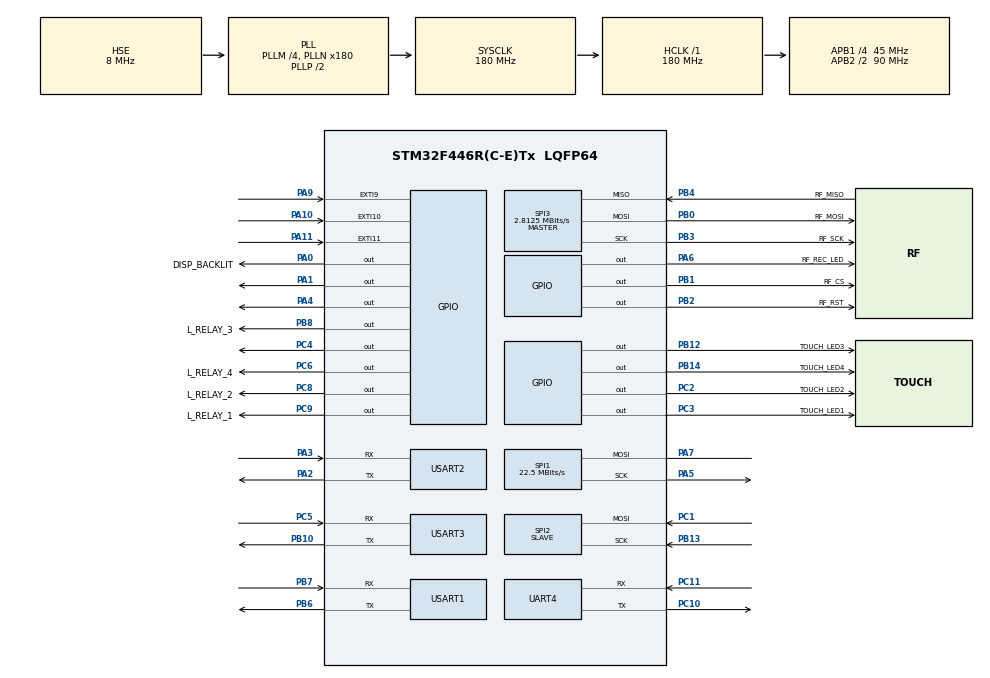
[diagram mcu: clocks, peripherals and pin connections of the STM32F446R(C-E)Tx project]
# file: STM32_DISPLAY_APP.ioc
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FATFS._USE_LABEL=1
IWDG.Prescaler=IWDG_PRESCALER_64
IWDG.Reload=1500
Mcu.Family=STM32F4
Mcu.Name=STM32F446R(C-E)Tx
Mcu.Package=LQFP64
NVIC.EXTI15_10_IRQn=true\:0\:0\:false\:false\:true\:true\:true\:true
NVIC.EXTI9_5_IRQn=true\:0\:0\:false\:false\:true\:true\:true\:true
NVIC.PriorityGroup=NVIC_PRIORITYGROUP_4
NVIC.RTC_Alarm_IRQn=true\:7\:0\:true\:false\:true\:true\:true\:true
NVIC.SPI2_IRQn=true\:5\:0\:true\:false\:true\:true\:true\:true
NVIC.TIM1_UP_TIM10_IRQn=true\:15\:0\:false\:false\:true\:false\:true\:true
NVIC.TimeBase=TIM1_UP_TIM10_IRQn
NVIC.TimeBaseIP=TIM1
NVIC.UART4_IRQn=true\:0\:0\:false\:false\:true\:true\:true\:true
NVIC.USART3_IRQn=true\:6\:0\:true\:false\:true\:true\:true\:true
PA0-WKUP.GPIO_Label=DISP_BACKLIT
PA0-WKUP.Signal=GPIO_Output
PA1.Signal=GPIO_Output
PA10.GPIO_ModeDefaultEXTI=GPIO_MODE_IT_FALLING
PA10.GPIO_PuPd=GPIO_PULLDOWN
PA10.Signal=GPXTI10
PA11.GPIO_ModeDefaultEXTI=GPIO_MODE_IT_FALLING
PA11.GPIO_PuPd=GPIO_PULLDOWN
PA11.Signal=GPXTI11
PA2.Mode=Asynchronous
PA2.Signal=USART2_TX
PA3.Mode=Asynchronous
PA3.Signal=USART2_RX
PA4.Signal=GPIO_Output
PA5.Mode=Simplex_Bidirectional_Master
PA5.Signal=SPI1_SCK
PA6.GPIO_Label=RF_REC_LED
PA6.Signal=GPIO_Output
PA7.Mode=Simplex_Bidirectional_Master
PA7.Signal=SPI1_MOSI
PA9.GPIO_ModeDefaultEXTI=GPIO_MODE_IT_FALLING
PA9.GPIO_PuPd=GPIO_PULLDOWN
PA9.Signal=GPXTI9
PB0.GPIO_Label=RF_MOSI
PB0.Mode=Full_Duplex_Master
PB0.Signal=SPI3_MOSI
PB1.GPIO_Label=RF_CS
PB1.Signal=GPIO_Output
PB10.Mode=Asynchronous
PB10.Signal=USART3_TX
PB12.GPIO_Label=TOUCH_LED3
PB12.Signal=GPIO_Output
PB13.Mode=RX_Only_Simplex_Unidirect_Slave
PB13.Signal=SPI2_SCK
PB14.GPIO_Label=TOUCH_LED4
PB14.Signal=GPIO_Output
PB2.GPIO_Label=RF_RST
PB2.Signal=GPIO_Output
PB3.GPIO_Label=RF_SCK
PB3.Mode=Full_Duplex_Master
PB3.Signal=SPI3_SCK
PB4.GPIO_Label=RF_MISO
PB4.Mode=Full_Duplex_Master
PB4.Signal=SPI3_MISO
PB6.Mode=Asynchronous
PB6.Signal=USART1_TX
PB7.Mode=Asynchronous
PB7.Signal=USART1_RX
PB8.GPIO_Label=L_RELAY_3
PB8.PinState=GPIO_PIN_SET
PB8.Signal=GPIO_Output
PC1.Mode=RX_Only_Simplex_Unidirect_Slave
PC1.Signal=SPI2_MOSI
PC10.Mode=Asynchronous
PC10.Signal=UART4_TX
PC11.Mode=Asynchronous
PC11.Signal=UART4_RX
PC14-OSC32_IN.Mode=LSE-External-Oscillator
PC14-OSC32_IN.Signal=RCC_OSC32_IN
PC15-OSC32_OUT.Mode=LSE-External-Oscillator
PC15-OSC32_OUT.Signal=RCC_OSC32_OUT
PC2.GPIO_Label=TOUCH_LED2
PC2.Signal=GPIO_Output
PC3.GPIO_Label=TOUCH_LED1
PC3.Signal=GPIO_Output
PC4.Signal=GPIO_Output
PC5.Mode=Asynchronous
PC5.Signal=USART3_RX
PC6.GPIO_Label=L_RELAY_4
PC6.GPIO_PuPd=GPIO_PULLDOWN
PC6.PinState=GPIO_PIN_RESET
PC6.Signal=GPIO_Output
PC8.GPIO_Label=L_RELAY_2
PC8.PinState=GPIO_PIN_SET
PC8.Signal=GPIO_Output
PC9.GPIO_Label=L_RELAY_1
PC9.PinState=GPIO_PIN_SET
PC9.Signal=GPIO_Output
PH0-OSC_IN.Mode=HSE-External-Oscillator
PH0-OSC_IN.Signal=RCC_OSC_IN
PH1-OSC_OUT.Mode=HSE-External-Oscillator
PH1-OSC_OUT.Signal=RCC_OSC_OUT
ProjectManager.HeapSize=0x200
ProjectManager.StackSize=0x400
ProjectManager.TargetToolchain=STM32CubeIDE
RCC.AHBFreq_Value=180000000
RCC.APB1CLKDivider=RCC_HCLK_DIV4
RCC.APB1Freq_Value=45000000
RCC.APB1TimFreq_Value=90000000
RCC.APB2CLKDivider=RCC_HCLK_DIV2
RCC.APB2Freq_Value=90000000
RCC.APB2TimFreq_Value=180000000
RCC.CortexFreq_Value=180000000
RCC.HCLKFreq_Value=180000000
RCC.HSE_VALUE=8000000
RCC.PLLM=4
RCC.PLLN=180
RCC.PLLSourceVirtual=RCC_PLLSOURCE_HSE
RCC.RCC_RTC_Clock_SourceVirtual=RCC_RTCCLKSOURCE_LSE
RCC.SYSCLKFreq_VALUE=180000000
RCC.SYSCLKSource=RCC_SYSCLKSOURCE_PLLCLK
RCC.USBFreq_Value=180000000
RCC.VCOOutputFreq_Value=360000000
RTC.Alarm=RTC_ALARM_A
RTC.Alarm_B=RTC_ALARM_B
RTC.HourFormat=RTC_HOURFORMAT_24
SPI1.BaudRatePrescaler=SPI_BAUDRATEPRESCALER_4
SPI1.CalculateBaudRate=22.5 MBits/s
SPI1.Direction=SPI_DIRECTION_1LINE
SPI1.Mode=SPI_MODE_MASTER
SPI1.VirtualType=VM_MASTER
SPI2.Direction=SPI_DIRECTION_2LINES_RXONLY
SPI2.Mode=SPI_MODE_SLAVE
SPI2.VirtualType=VM_SLAVE
SPI3.BaudRatePrescaler=SPI_BAUDRATEPRESCALER_16
SPI3.CalculateBaudRate=2.8125 MBits/s
SPI3.Direction=SPI_DIRECTION_2LINES
SPI3.Mode=SPI_MODE_MASTER
SPI3.VirtualType=VM_MASTER
UART4.VirtualMode=Asynchronous
USART1.VirtualMode=VM_ASYNC
USART2.VirtualMode=VM_ASYNC
USART3.VirtualMode=VM_ASYNC
VP_FATFS_VS_Generic.Mode=User_defined
VP_IWDG_VS_IWDG.Mode=IWDG_Activate
VP_RTC_VS_RTC_Activate.Mode=RTC_Enabled
VP_RTC_VS_RTC_Alarm_A_Intern.Mode=Alarm A
VP_RTC_VS_RTC_Alarm_B_Intern.Mode=Alarm B
VP_RTC_VS_RTC_Calendar.Mode=RTC_Calendar
VP_SYS_VS_tim1.Mode=TIM1
board=custom

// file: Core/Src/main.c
/* USER CODE BEGIN Header */
/**
  ******************************************************************************
  * @file           : main.c
  * @brief          : Main program body
  ******************************************************************************
  * @attention
  *
  * Copyright (c) 2025 STMicroelectronics.
  * All rights reserved.
  *
  * This software is licensed under terms that can be found in the LICENSE file
  * in the root directory of this software component.
  * If no LICENSE file comes with this software, it is provided AS-IS.
  *
  ******************************************************************************
  */
/* USER CODE END Header */
#include "main.h"
#include "fatfs.h"

/* USER CODE BEGIN Includes */
#include "user_app.h"
/* USER CODE END Includes */

IWDG_HandleTypeDef hiwdg;

RTC_HandleTypeDef hrtc;

SPI_HandleTypeDef hspi1;
SPI_HandleTypeDef hspi2;
SPI_HandleTypeDef hspi3;

UART_HandleTypeDef huart4;
UART_HandleTypeDef huart1;
UART_HandleTypeDef huart2;
UART_HandleTypeDef huart3;

void SystemClock_Config(void);
static void MX_GPIO_Init(void);
static void MX_SPI1_Init(void);
static void MX_SPI2_Init(void);
static void MX_USART2_UART_Init(void);
static void MX_USART3_UART_Init(void);
static void MX_SPI3_Init(void);
static void MX_UART4_Init(void);
static void MX_USART1_UART_Init(void);
static void MX_RTC_Init(void);
void MX_IWDG_Init(void);

/* USER CODE BEGIN 0 */
#ifdef __GNUC__
#define UART_printf   int __io_putchar(int ch)
UART_printf
{
	HAL_UART_Transmit(&huart2, (uint8_t*)&ch, 1, HAL_MAX_DELAY);
	return ch;
}
#endif
/* USER CODE END 0 */

int main(void)
{

  /* MCU Configuration--------------------------------------------------------*/

  /* Reset of all peripherals, Initializes the Flash interface and the Systick. */
  HAL_Init();

  /* Configure the system clock */
  SystemClock_Config();

  /* Initialize all configured peripherals */
  MX_GPIO_Init();
  MX_SPI1_Init();
  MX_SPI2_Init();
  MX_USART2_UART_Init();
  MX_USART3_UART_Init();
  MX_SPI3_Init();
  MX_UART4_Init();
  MX_USART1_UART_Init();
  MX_RTC_Init();
 // MX_IWDG_Init();
  /* USER CODE BEGIN 2 */
  user_app_init();
  /* USER CODE END 2 */

  /* Infinite loop */
  while (1)
  {

  }
}

void SystemClock_Config(void)
{
  RCC_OscInitTypeDef RCC_OscInitStruct = {0};
  RCC_ClkInitTypeDef RCC_ClkInitStruct = {0};

  /** Configure the main internal regulator output voltage
  */
  __HAL_RCC_PWR_CLK_ENABLE();
  __HAL_PWR_VOLTAGESCALING_CONFIG(PWR_REGULATOR_VOLTAGE_SCALE1);

  /** Initializes the RCC Oscillators according to the specified parameters
  * in the RCC_OscInitTypeDef structure.
  */
  RCC_OscInitStruct.OscillatorType = RCC_OSCILLATORTYPE_LSI|RCC_OSCILLATORTYPE_HSE
                              |RCC_OSCILLATORTYPE_LSE;
  RCC_OscInitStruct.HSEState = RCC_HSE_ON;
  RCC_OscInitStruct.LSEState = RCC_LSE_ON;
  RCC_OscInitStruct.LSIState = RCC_LSI_ON;
  RCC_OscInitStruct.PLL.PLLState = RCC_PLL_ON;
  RCC_OscInitStruct.PLL.PLLSource = RCC_PLLSOURCE_HSE;
  RCC_OscInitStruct.PLL.PLLM = 4;
  RCC_OscInitStruct.PLL.PLLN = 180;
  RCC_OscInitStruct.PLL.PLLP = RCC_PLLP_DIV2;
  RCC_OscInitStruct.PLL.PLLQ = 2;
  RCC_OscInitStruct.PLL.PLLR = 2;
  if (HAL_RCC_OscConfig(&RCC_OscInitStruct) != HAL_OK)
  {
    Error_Handler();
  }

  /** Activate the Over-Drive mode
  */
  if (HAL_PWREx_EnableOverDrive() != HAL_OK)
  {
    Error_Handler();
  }

  /** Initializes the CPU, AHB and APB buses clocks
  */
  RCC_ClkInitStruct.ClockType = RCC_CLOCKTYPE_HCLK|RCC_CLOCKTYPE_SYSCLK
                              |RCC_CLOCKTYPE_PCLK1|RCC_CLOCKTYPE_PCLK2;
  RCC_ClkInitStruct.SYSCLKSource = RCC_SYSCLKSOURCE_PLLCLK;
  RCC_ClkInitStruct.AHBCLKDivider = RCC_SYSCLK_DIV1;
  RCC_ClkInitStruct.APB1CLKDivider = RCC_HCLK_DIV4;
  RCC_ClkInitStruct.APB2CLKDivider = RCC_HCLK_DIV2;

  if (HAL_RCC_ClockConfig(&RCC_ClkInitStruct, FLASH_LATENCY_5) != HAL_OK)
  {
    Error_Handler();
  }
}

void MX_IWDG_Init(void)
{

  hiwdg.Instance = IWDG;
  hiwdg.Init.Prescaler = IWDG_PRESCALER_64;
  hiwdg.Init.Reload = 1500;
  if (HAL_IWDG_Init(&hiwdg) != HAL_OK)
  {
    Error_Handler();
  }

}

static void MX_RTC_Init(void)
{

//  RTC_TimeTypeDef sTime = {0};
//  RTC_DateTypeDef sDate = {0};
//  RTC_AlarmTypeDef sAlarm = {0};

  /* USER CODE BEGIN RTC_Init 1 */
//
  /* USER CODE END RTC_Init 1 */

  /** Initialize RTC Only
  */
  hrtc.Instance = RTC;
  hrtc.Init.HourFormat = RTC_HOURFORMAT_24;
  hrtc.Init.AsynchPrediv = 127;
  hrtc.Init.SynchPrediv = 255;
  hrtc.Init.OutPut = RTC_OUTPUT_DISABLE;
  hrtc.Init.OutPutPolarity = RTC_OUTPUT_POLARITY_HIGH;
  hrtc.Init.OutPutType = RTC_OUTPUT_TYPE_OPENDRAIN;
  if (HAL_RTC_Init(&hrtc) != HAL_OK)
  {
    Error_Handler();
  }

  /* USER CODE BEGIN Check_RTC_BKUP */
//
  /* USER CODE END Check_RTC_BKUP */

  /** Initialize RTC and set the Time and Date
  */
//  sTime.Hours = 0x0;
//  sTime.Minutes = 0x0;
//  sTime.Seconds = 0x0;
//  sTime.DayLightSaving = RTC_DAYLIGHTSAVING_NONE;
//  sTime.StoreOperation = RTC_STOREOPERATION_RESET;
//  if (HAL_RTC_SetTime(&hrtc, &sTime, RTC_FORMAT_BCD) != HAL_OK)
//  {
//    Error_Handler();
//  }
//  sDate.WeekDay = RTC_WEEKDAY_MONDAY;
//  sDate.Month = RTC_MONTH_JANUARY;
//  sDate.Date = 0x1;
//  sDate.Year = 0x0;
//
//  if (HAL_RTC_SetDate(&hrtc, &sDate, RTC_FORMAT_BCD) != HAL_OK)
//  {
//    Error_Handler();
//  }
//
//  /** Enable the Alarm A
//  */
//  sAlarm.AlarmTime.Hours = 0x0;
//  sAlarm.AlarmTime.Minutes = 0x0;
//  sAlarm.AlarmTime.Seconds = 0x0;
//  sAlarm.AlarmTime.SubSeconds = 0x0;
//  sAlarm.AlarmTime.DayLightSaving = RTC_DAYLIGHTSAVING_NONE;
//  sAlarm.AlarmTime.StoreOperation = RTC_STOREOPERATION_RESET;
//  sAlarm.AlarmMask = RTC_ALARMMASK_NONE;
//  sAlarm.AlarmSubSecondMask = RTC_ALARMSUBSECONDMASK_ALL;
//  sAlarm.AlarmDateWeekDaySel = RTC_ALARMDATEWEEKDAYSEL_DATE;
//  sAlarm.AlarmDateWeekDay = 0x1;
//  sAlarm.Alarm = RTC_ALARM_A;
//  if (HAL_RTC_SetAlarm_IT(&hrtc, &sAlarm, RTC_FORMAT_BCD) != HAL_OK)
//  {
//    Error_Handler();
//  }
//
//  /** Enable the Alarm B
//  */
//  sAlarm.Alarm = RTC_ALARM_B;
//  if (HAL_RTC_SetAlarm_IT(&hrtc, &sAlarm, RTC_FORMAT_BCD) != HAL_OK)
//  {
//    Error_Handler();
//  }

}

static void MX_SPI1_Init(void)
{

  /* SPI1 parameter configuration*/
  hspi1.Instance = SPI1;
  hspi1.Init.Mode = SPI_MODE_MASTER;
  hspi1.Init.Direction = SPI_DIRECTION_1LINE;
  hspi1.Init.DataSize = SPI_DATASIZE_8BIT;
  hspi1.Init.CLKPolarity = SPI_POLARITY_LOW;
  hspi1.Init.CLKPhase = SPI_PHASE_1EDGE;
  hspi1.Init.NSS = SPI_NSS_SOFT;
  hspi1.Init.BaudRatePrescaler = SPI_BAUDRATEPRESCALER_4;
  hspi1.Init.FirstBit = SPI_FIRSTBIT_MSB;
  hspi1.Init.TIMode = SPI_TIMODE_DISABLE;
  hspi1.Init.CRCCalculation = SPI_CRCCALCULATION_DISABLE;
  hspi1.Init.CRCPolynomial = 10;
  if (HAL_SPI_Init(&hspi1) != HAL_OK)
  {
    Error_Handler();
  }

}

static void MX_SPI2_Init(void)
{

  /* SPI2 parameter configuration*/
  hspi2.Instance = SPI2;
  hspi2.Init.Mode = SPI_MODE_SLAVE;
  hspi2.Init.Direction = SPI_DIRECTION_2LINES_RXONLY;
  hspi2.Init.DataSize = SPI_DATASIZE_8BIT;
  hspi2.Init.CLKPolarity = SPI_POLARITY_LOW;
  hspi2.Init.CLKPhase = SPI_PHASE_1EDGE;
  hspi2.Init.NSS = SPI_NSS_SOFT;
  hspi2.Init.FirstBit = SPI_FIRSTBIT_MSB;
  hspi2.Init.TIMode = SPI_TIMODE_DISABLE;
  hspi2.Init.CRCCalculation = SPI_CRCCALCULATION_DISABLE;
  hspi2.Init.CRCPolynomial = 10;
  if (HAL_SPI_Init(&hspi2) != HAL_OK)
  {
    Error_Handler();
  }

}

static void MX_SPI3_Init(void)
{

  /* SPI3 parameter configuration*/
  hspi3.Instance = SPI3;
  hspi3.Init.Mode = SPI_MODE_MASTER;
  hspi3.Init.Direction = SPI_DIRECTION_2LINES;
  hspi3.Init.DataSize = SPI_DATASIZE_8BIT;
  hspi3.Init.CLKPolarity = SPI_POLARITY_LOW;
  hspi3.Init.CLKPhase = SPI_PHASE_1EDGE;
  hspi3.Init.NSS = SPI_NSS_SOFT;
  hspi3.Init.BaudRatePrescaler = SPI_BAUDRATEPRESCALER_16;
  hspi3.Init.FirstBit = SPI_FIRSTBIT_MSB;
  hspi3.Init.TIMode = SPI_TIMODE_DISABLE;
  hspi3.Init.CRCCalculation = SPI_CRCCALCULATION_DISABLE;
  hspi3.Init.CRCPolynomial = 10;
  if (HAL_SPI_Init(&hspi3) != HAL_OK)
  {
    Error_Handler();
  }

}

static void MX_UART4_Init(void)
{

  huart4.Instance = UART4;
  huart4.Init.BaudRate = 115200;
  huart4.Init.WordLength = UART_WORDLENGTH_8B;
  huart4.Init.StopBits = UART_STOPBITS_1;
  huart4.Init.Parity = UART_PARITY_NONE;
  huart4.Init.Mode = UART_MODE_TX_RX;
  huart4.Init.HwFlowCtl = UART_HWCONTROL_NONE;
  huart4.Init.OverSampling = UART_OVERSAMPLING_16;
  if (HAL_UART_Init(&huart4) != HAL_OK)
  {
    Error_Handler();
  }

}

static void MX_USART1_UART_Init(void)
{

  huart1.Instance = USART1;
  huart1.Init.BaudRate = 115200;
  huart1.Init.WordLength = UART_WORDLENGTH_8B;
  huart1.Init.StopBits = UART_STOPBITS_1;
  huart1.Init.Parity = UART_PARITY_NONE;
  huart1.Init.Mode = UART_MODE_TX_RX;
  huart1.Init.HwFlowCtl = UART_HWCONTROL_NONE;
  huart1.Init.OverSampling = UART_OVERSAMPLING_16;
  if (HAL_UART_Init(&huart1) != HAL_OK)
  {
    Error_Handler();
  }

}

static void MX_USART2_UART_Init(void)
{

  huart2.Instance = USART2;
  huart2.Init.BaudRate = 115200;
  huart2.Init.WordLength = UART_WORDLENGTH_8B;
  huart2.Init.StopBits = UART_STOPBITS_1;
  huart2.Init.Parity = UART_PARITY_NONE;
  huart2.Init.Mode = UART_MODE_TX_RX;
  huart2.Init.HwFlowCtl = UART_HWCONTROL_NONE;
  huart2.Init.OverSampling = UART_OVERSAMPLING_16;
  if (HAL_UART_Init(&huart2) != HAL_OK)
  {
    Error_Handler();
  }

}

static void MX_USART3_UART_Init(void)
{

  huart3.Instance = USART3;
  huart3.Init.BaudRate = 115200;
  huart3.Init.WordLength = UART_WORDLENGTH_8B;
  huart3.Init.StopBits = UART_STOPBITS_1;
  huart3.Init.Parity = UART_PARITY_NONE;
  huart3.Init.Mode = UART_MODE_TX_RX;
  huart3.Init.HwFlowCtl = UART_HWCONTROL_NONE;
  huart3.Init.OverSampling = UART_OVERSAMPLING_16;
  if (HAL_UART_Init(&huart3) != HAL_OK)
  {
    Error_Handler();
  }

}

static void MX_GPIO_Init(void)
{
  GPIO_InitTypeDef GPIO_InitStruct = {0};

  /* GPIO Ports Clock Enable */
  __HAL_RCC_GPIOC_CLK_ENABLE();
  __HAL_RCC_GPIOH_CLK_ENABLE();
  __HAL_RCC_GPIOA_CLK_ENABLE();
  __HAL_RCC_GPIOB_CLK_ENABLE();

  /*Configure GPIO pin Output Level */
  HAL_GPIO_WritePin(GPIOC, TOUCH_LED2_Pin|TOUCH_LED1_Pin|GPIO_PIN_4|L_RELAY_4_Pin, GPIO_PIN_RESET);

  /*Configure GPIO pin Output Level */
  HAL_GPIO_WritePin(GPIOA, DISP_BACKLIT_Pin|GPIO_PIN_1|GPIO_PIN_4|RF_REC_LED_Pin, GPIO_PIN_RESET);

  /*Configure GPIO pin Output Level */
  HAL_GPIO_WritePin(GPIOB, RF_CS_Pin|RF_RST_Pin|TOUCH_LED3_Pin|TOUCH_LED4_Pin, GPIO_PIN_RESET);

  /*Configure GPIO pin Output Level */
  HAL_GPIO_WritePin(GPIOC, L_RELAY_2_Pin|L_RELAY_1_Pin, GPIO_PIN_SET);

  /*Configure GPIO pin Output Level */
  HAL_GPIO_WritePin(L_RELAY_3_GPIO_Port, L_RELAY_3_Pin, GPIO_PIN_SET);

  /*Configure GPIO pins : TOUCH_LED2_Pin TOUCH_LED1_Pin PC4 L_RELAY_2_Pin
                           L_RELAY_1_Pin */
  GPIO_InitStruct.Pin = TOUCH_LED2_Pin|TOUCH_LED1_Pin|GPIO_PIN_4|L_RELAY_2_Pin
                          |L_RELAY_1_Pin;
  GPIO_InitStruct.Mode = GPIO_MODE_OUTPUT_PP;
  GPIO_InitStruct.Pull = GPIO_NOPULL;
  GPIO_InitStruct.Speed = GPIO_SPEED_FREQ_LOW;
  HAL_GPIO_Init(GPIOC, &GPIO_InitStruct);

  /*Configure GPIO pins : DISP_BACKLIT_Pin PA1 PA4 RF_REC_LED_Pin */
  GPIO_InitStruct.Pin = DISP_BACKLIT_Pin|GPIO_PIN_1|GPIO_PIN_4|RF_REC_LED_Pin;
  GPIO_InitStruct.Mode = GPIO_MODE_OUTPUT_PP;
  GPIO_InitStruct.Pull = GPIO_NOPULL;
  GPIO_InitStruct.Speed = GPIO_SPEED_FREQ_LOW;
  HAL_GPIO_Init(GPIOA, &GPIO_InitStruct);

  /*Configure GPIO pins : RF_CS_Pin RF_RST_Pin TOUCH_LED3_Pin TOUCH_LED4_Pin
                           L_RELAY_3_Pin */
  GPIO_InitStruct.Pin = RF_CS_Pin|RF_RST_Pin|TOUCH_LED3_Pin|TOUCH_LED4_Pin
                          |L_RELAY_3_Pin;
  GPIO_InitStruct.Mode = GPIO_MODE_OUTPUT_PP;
  GPIO_InitStruct.Pull = GPIO_NOPULL;
  GPIO_InitStruct.Speed = GPIO_SPEED_FREQ_LOW;
  HAL_GPIO_Init(GPIOB, &GPIO_InitStruct);

  /*Configure GPIO pin : L_RELAY_4_Pin */
  GPIO_InitStruct.Pin = L_RELAY_4_Pin;
  GPIO_InitStruct.Mode = GPIO_MODE_OUTPUT_PP;
  GPIO_InitStruct.Pull = GPIO_PULLDOWN;
  GPIO_InitStruct.Speed = GPIO_SPEED_FREQ_LOW;
  HAL_GPIO_Init(L_RELAY_4_GPIO_Port, &GPIO_InitStruct);

  /*Configure GPIO pins : PA9 PA10 PA11 */
  GPIO_InitStruct.Pin = GPIO_PIN_9|GPIO_PIN_10|GPIO_PIN_11;
  GPIO_InitStruct.Mode = GPIO_MODE_IT_FALLING;
  GPIO_InitStruct.Pull = GPIO_PULLDOWN;
  HAL_GPIO_Init(GPIOA, &GPIO_InitStruct);

  /* EXTI interrupt init*/
  HAL_NVIC_SetPriority(EXTI9_5_IRQn, 0, 0);
  HAL_NVIC_EnableIRQ(EXTI9_5_IRQn);

  HAL_NVIC_SetPriority(EXTI15_10_IRQn, 0, 0);
  HAL_NVIC_EnableIRQ(EXTI15_10_IRQn);

}

void HAL_TIM_PeriodElapsedCallback(TIM_HandleTypeDef *htim)
{
  if (htim->Instance == TIM1)
  {
    HAL_IncTick();
  }
}

void Error_Handler(void)
{
  __disable_irq();
  while (1)
  {
  }
}
